VERSION ""

NS_ :

BS_:

BU_: IMU C70 PIT IRTEMP

BO_ 1791 C70_BrakePressures: 8 C70
 SG_ C70_BrakePressureFront : 0|16@1- (0.2,1250) [0|2500] "psi" Vector__XXX
 SG_ C70_BrakePressureRear : 16|16@1- (0.2,1250) [0|2500] "psi" Vector__XXX

BO_ 368 IMU_Sync: 8 Vector__XXX

BO_ 372 IMU_Tx1: 8 IMU
 SG_ IMU_Yaw_Rate : 0|16@1+ (0.005,-163.84) [-163.84|163.83] "deg/s" Vector__XXX
 SG_ IMU_Accel_Y : 32|16@1+ (0.000127465,-4.1768) [-4.1768|4.1765] "g" Vector__XXX

BO_ 376 IMU_Tx2: 8 IMU
 SG_ IMU_Roll_Rate : 0|16@1+ (0.005,-163.84) [-163.84|163.835] "deg/s" Vector__XXX
 SG_ IMU_Accel_X : 32|16@1+ (0.000127465,-4.1768) [-4.1768|4.1765] "g" Vector__XXX

BO_ 380 IMU_Tx3: 8 IMU
 SG_ IMU_Accel_Z : 32|16@1+ (0.000127465,-4.1768) [-4.1768|4.1765] "g" Vector__XXX

BO_ 384 PIT_Pressures: 8 PIT
 SG_ PIT_PressureMux M : 0|8@1+ (1,0) [0|255] "" Vector__XXX
 SG_ PIT_Pressure1 m0 : 15|16@0+ (0.01,600) [600|1200] "mbar" Vector__XXX
 SG_ PIT_Pressure2 m0 : 31|16@0+ (0.01,600) [600|1200] "mbar" Vector__XXX
 SG_ PIT_Pressure3 m0 : 47|16@0+ (0.01,600) [600|1200] "mbar" Vector__XXX
 SG_ PIT_PressureRange m0 : 56|8@1+ (1,0) [0|3] "" Vector__XXX
 SG_ PIT_Pressure4 m1 : 15|16@0+ (0.01,600) [600|1200] "mbar" Vector__XXX
 SG_ PIT_Pressure5 m1 : 31|16@0+ (0.01,600) [600|1200] "mbar" Vector__XXX
 SG_ PIT_Pressure6 m1 : 47|16@0+ (0.01,600) [600|1200] "mbar" Vector__XXX
 SG_ PIT_Temperature m1 : 56|8@1- (1,0) [0|0] "degC" Vector__XXX
 SG_ PIT_Pressure7 m2 : 15|16@0+ (0.01,600) [600|1200] "mbar" Vector__XXX
 SG_ PIT_Pressure8 m2 : 31|16@0+ (0.01,600) [600|1200] "mbar" Vector__XXX
 SG_ PIT_SensorNum m2 : 47|16@0+ (1,0) [0|0] "" Vector__XXX

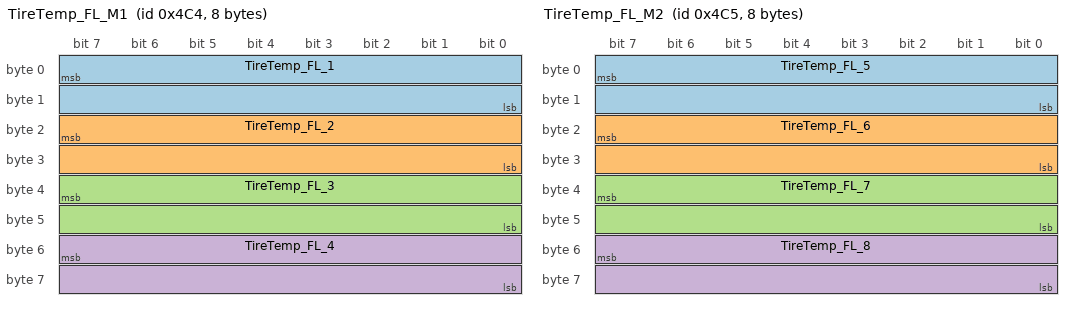
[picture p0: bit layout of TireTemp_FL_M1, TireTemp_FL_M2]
BO_ 1220 TireTemp_FL_M1: 8 IRTEMP
 SG_ TireTemp_FL_1 : 7|16@0+ (0.1,-100) [-20|950] "degC" Vector__XXX
 SG_ TireTemp_FL_2 : 23|16@0+ (0.1,-100) [-20|950] "degC" Vector__XXX
 SG_ TireTemp_FL_3 : 39|16@0+ (0.1,-100) [-20|950] "degC" Vector__XXX
 SG_ TireTemp_FL_4 : 55|16@0+ (0.1,-100) [-20|950] "degC" Vector__XXX

BO_ 1221 TireTemp_FL_M2: 8 IRTEMP
 SG_ TireTemp_FL_5 : 7|16@0+ (0.1,-100) [-20|950] "degC" Vector__XXX
 SG_ TireTemp_FL_6 : 23|16@0+ (0.1,-100) [-20|950] "degC" Vector__XXX
 SG_ TireTemp_FL_7 : 39|16@0+ (0.1,-100) [-20|950] "degC" Vector__XXX
 SG_ TireTemp_FL_8 : 55|16@0+ (0.1,-100) [-20|950] "degC" Vector__XXX

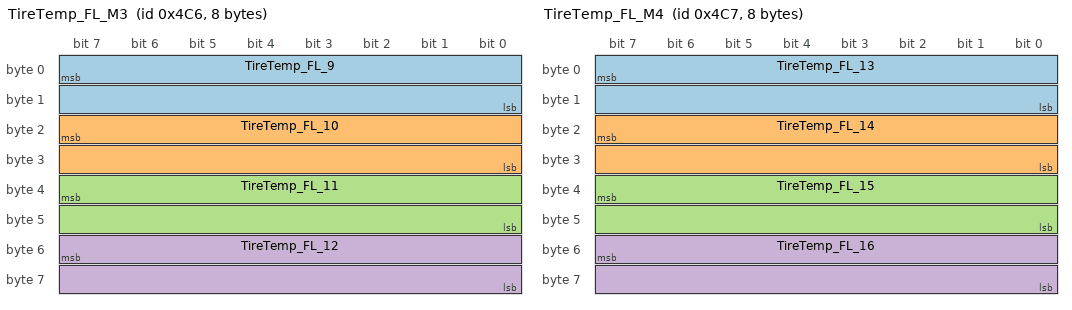
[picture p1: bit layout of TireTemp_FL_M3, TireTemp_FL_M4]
BO_ 1222 TireTemp_FL_M3: 8 IRTEMP
 SG_ TireTemp_FL_9 : 7|16@0+ (0.1,-100) [-20|950] "degC" Vector__XXX
 SG_ TireTemp_FL_10 : 23|16@0+ (0.1,-100) [-20|950] "degC" Vector__XXX
 SG_ TireTemp_FL_11 : 39|16@0+ (0.1,-100) [-20|950] "degC" Vector__XXX
 SG_ TireTemp_FL_12 : 55|16@0+ (0.1,-100) [-20|950] "degC" Vector__XXX

BO_ 1223 TireTemp_FL_M4: 8 IRTEMP
 SG_ TireTemp_FL_13 : 7|16@0+ (0.1,-100) [-20|950] "degC" Vector__XXX
 SG_ TireTemp_FL_14 : 23|16@0+ (0.1,-100) [-20|950] "degC" Vector__XXX
 SG_ TireTemp_FL_15 : 39|16@0+ (0.1,-100) [-20|950] "degC" Vector__XXX
 SG_ TireTemp_FL_16 : 55|16@0+ (0.1,-100) [-20|950] "degC" Vector__XXX

BO_ 1224 TireTemp_FL_M5: 8 IRTEMP
 SG_ TireTemp_FL_Sensor : 7|16@0+ (0.1,-100) [-20|85] "degC" Vector__XXX

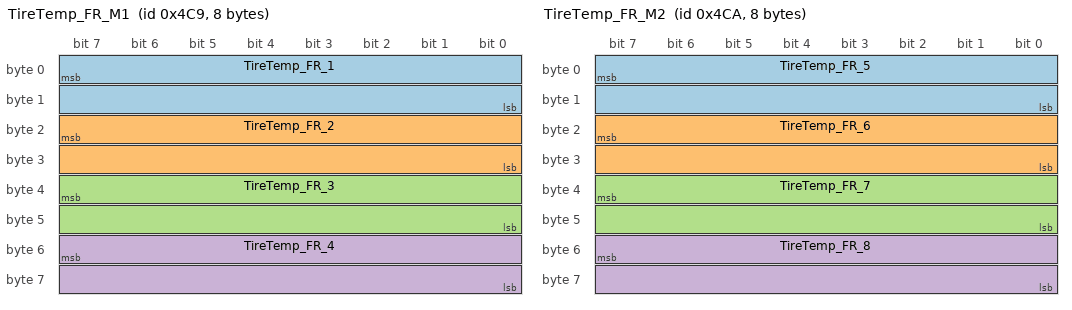
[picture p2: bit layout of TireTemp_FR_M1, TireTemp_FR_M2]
BO_ 1225 TireTemp_FR_M1: 8 IRTEMP
 SG_ TireTemp_FR_1 : 7|16@0+ (0.1,-100) [-20|950] "degC" Vector__XXX
 SG_ TireTemp_FR_2 : 23|16@0+ (0.1,-100) [-20|950] "degC" Vector__XXX
 SG_ TireTemp_FR_3 : 39|16@0+ (0.1,-100) [-20|950] "degC" Vector__XXX
 SG_ TireTemp_FR_4 : 55|16@0+ (0.1,-100) [-20|950] "degC" Vector__XXX

BO_ 1226 TireTemp_FR_M2: 8 IRTEMP
 SG_ TireTemp_FR_5 : 7|16@0+ (0.1,-100) [-20|950] "degC" Vector__XXX
 SG_ TireTemp_FR_6 : 23|16@0+ (0.1,-100) [-20|950] "degC" Vector__XXX
 SG_ TireTemp_FR_7 : 39|16@0+ (0.1,-100) [-20|950] "degC" Vector__XXX
 SG_ TireTemp_FR_8 : 55|16@0+ (0.1,-100) [-20|950] "degC" Vector__XXX

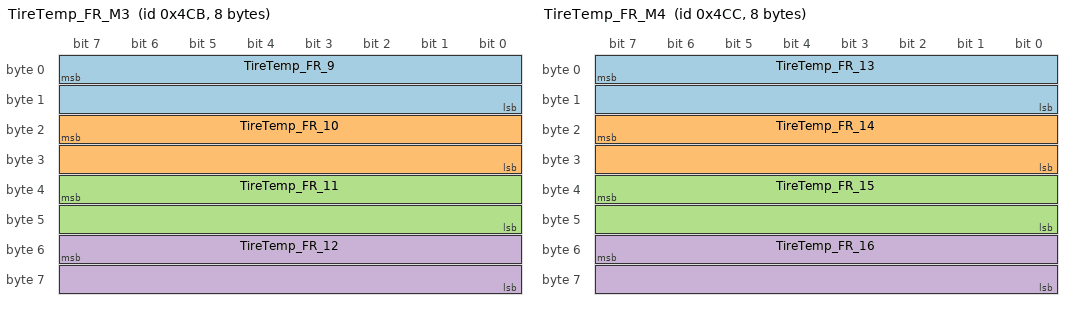
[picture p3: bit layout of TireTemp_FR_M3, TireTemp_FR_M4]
BO_ 1227 TireTemp_FR_M3: 8 IRTEMP
 SG_ TireTemp_FR_9 : 7|16@0+ (0.1,-100) [-20|950] "degC" Vector__XXX
 SG_ TireTemp_FR_10 : 23|16@0+ (0.1,-100) [-20|950] "degC" Vector__XXX
 SG_ TireTemp_FR_11 : 39|16@0+ (0.1,-100) [-20|950] "degC" Vector__XXX
 SG_ TireTemp_FR_12 : 55|16@0+ (0.1,-100) [-20|950] "degC" Vector__XXX

BO_ 1228 TireTemp_FR_M4: 8 IRTEMP
 SG_ TireTemp_FR_13 : 7|16@0+ (0.1,-100) [-20|950] "degC" Vector__XXX
 SG_ TireTemp_FR_14 : 23|16@0+ (0.1,-100) [-20|950] "degC" Vector__XXX
 SG_ TireTemp_FR_15 : 39|16@0+ (0.1,-100) [-20|950] "degC" Vector__XXX
 SG_ TireTemp_FR_16 : 55|16@0+ (0.1,-100) [-20|950] "degC" Vector__XXX

BO_ 1229 TireTemp_FR_M5: 8 IRTEMP
 SG_ TireTemp_FR_Sensor : 7|16@0+ (0.1,-100) [-20|85] "degC" Vector__XXX

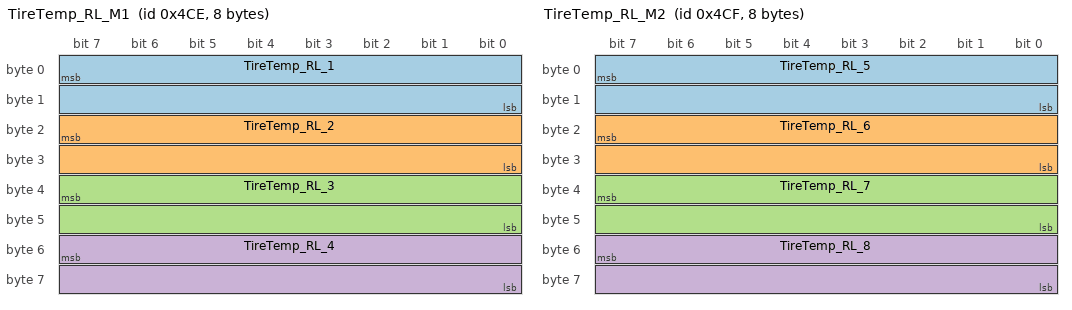
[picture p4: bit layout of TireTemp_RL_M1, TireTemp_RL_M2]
BO_ 1230 TireTemp_RL_M1: 8 IRTEMP
 SG_ TireTemp_RL_1 : 7|16@0+ (0.1,-100) [-20|950] "degC" Vector__XXX
 SG_ TireTemp_RL_2 : 23|16@0+ (0.1,-100) [-20|950] "degC" Vector__XXX
 SG_ TireTemp_RL_3 : 39|16@0+ (0.1,-100) [-20|950] "degC" Vector__XXX
 SG_ TireTemp_RL_4 : 55|16@0+ (0.1,-100) [-20|950] "degC" Vector__XXX

BO_ 1231 TireTemp_RL_M2: 8 IRTEMP
 SG_ TireTemp_RL_5 : 7|16@0+ (0.1,-100) [-20|950] "degC" Vector__XXX
 SG_ TireTemp_RL_6 : 23|16@0+ (0.1,-100) [-20|950] "degC" Vector__XXX
 SG_ TireTemp_RL_7 : 39|16@0+ (0.1,-100) [-20|950] "degC" Vector__XXX
 SG_ TireTemp_RL_8 : 55|16@0+ (0.1,-100) [-20|950] "degC" Vector__XXX

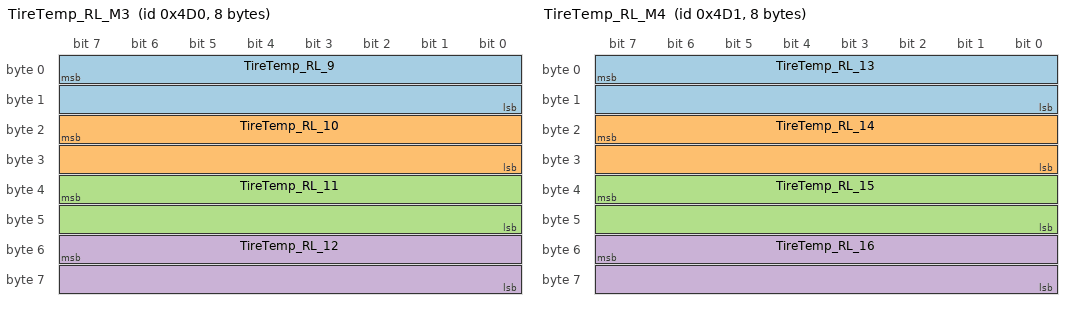
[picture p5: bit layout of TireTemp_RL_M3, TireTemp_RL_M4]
BO_ 1232 TireTemp_RL_M3: 8 IRTEMP
 SG_ TireTemp_RL_9 : 7|16@0+ (0.1,-100) [-20|950] "degC" Vector__XXX
 SG_ TireTemp_RL_10 : 23|16@0+ (0.1,-100) [-20|950] "degC" Vector__XXX
 SG_ TireTemp_RL_11 : 39|16@0+ (0.1,-100) [-20|950] "degC" Vector__XXX
 SG_ TireTemp_RL_12 : 55|16@0+ (0.1,-100) [-20|950] "degC" Vector__XXX

BO_ 1233 TireTemp_RL_M4: 8 IRTEMP
 SG_ TireTemp_RL_13 : 7|16@0+ (0.1,-100) [-20|950] "degC" Vector__XXX
 SG_ TireTemp_RL_14 : 23|16@0+ (0.1,-100) [-20|950] "degC" Vector__XXX
 SG_ TireTemp_RL_15 : 39|16@0+ (0.1,-100) [-20|950] "degC" Vector__XXX
 SG_ TireTemp_RL_16 : 55|16@0+ (0.1,-100) [-20|950] "degC" Vector__XXX

BO_ 1234 TireTemp_RL_M5: 8 IRTEMP
 SG_ TireTemp_RL_Sensor : 7|16@0+ (0.1,-100) [-20|85] "degC" Vector__XXX

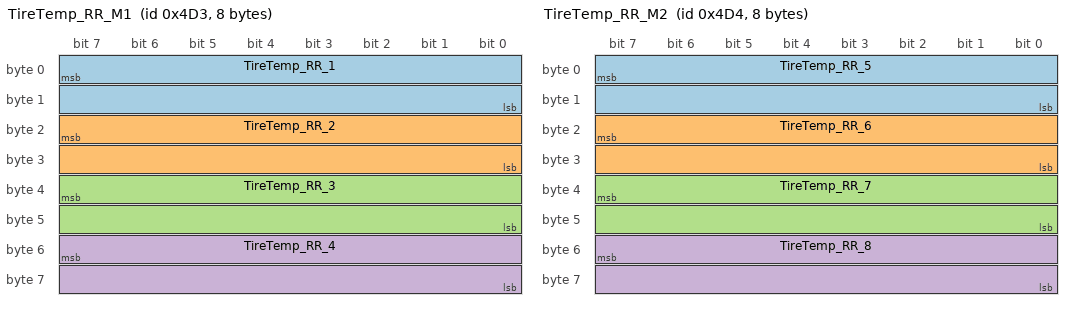
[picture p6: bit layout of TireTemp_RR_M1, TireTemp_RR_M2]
BO_ 1235 TireTemp_RR_M1: 8 IRTEMP
 SG_ TireTemp_RR_1 : 7|16@0+ (0.1,-100) [-20|950] "degC" Vector__XXX
 SG_ TireTemp_RR_2 : 23|16@0+ (0.1,-100) [-20|950] "degC" Vector__XXX
 SG_ TireTemp_RR_3 : 39|16@0+ (0.1,-100) [-20|950] "degC" Vector__XXX
 SG_ TireTemp_RR_4 : 55|16@0+ (0.1,-100) [-20|950] "degC" Vector__XXX

BO_ 1236 TireTemp_RR_M2: 8 IRTEMP
 SG_ TireTemp_RR_5 : 7|16@0+ (0.1,-100) [-20|950] "degC" Vector__XXX
 SG_ TireTemp_RR_6 : 23|16@0+ (0.1,-100) [-20|950] "degC" Vector__XXX
 SG_ TireTemp_RR_7 : 39|16@0+ (0.1,-100) [-20|950] "degC" Vector__XXX
 SG_ TireTemp_RR_8 : 55|16@0+ (0.1,-100) [-20|950] "degC" Vector__XXX

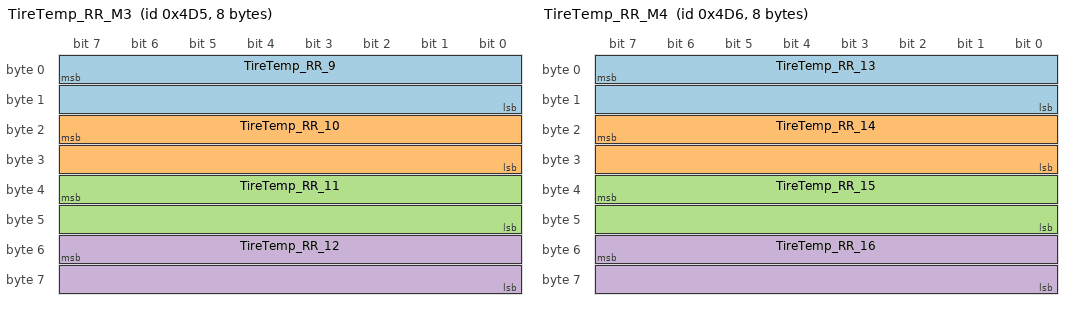
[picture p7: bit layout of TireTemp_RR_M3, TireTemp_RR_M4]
BO_ 1237 TireTemp_RR_M3: 8 IRTEMP
 SG_ TireTemp_RR_9 : 7|16@0+ (0.1,-100) [-20|950] "degC" Vector__XXX
 SG_ TireTemp_RR_10 : 23|16@0+ (0.1,-100) [-20|950] "degC" Vector__XXX
 SG_ TireTemp_RR_11 : 39|16@0+ (0.1,-100) [-20|950] "degC" Vector__XXX
 SG_ TireTemp_RR_12 : 55|16@0+ (0.1,-100) [-20|950] "degC" Vector__XXX

BO_ 1238 TireTemp_RR_M4: 8 IRTEMP
 SG_ TireTemp_RR_13 : 7|16@0+ (0.1,-100) [-20|950] "degC" Vector__XXX
 SG_ TireTemp_RR_14 : 23|16@0+ (0.1,-100) [-20|950] "degC" Vector__XXX
 SG_ TireTemp_RR_15 : 39|16@0+ (0.1,-100) [-20|950] "degC" Vector__XXX
 SG_ TireTemp_RR_16 : 55|16@0+ (0.1,-100) [-20|950] "degC" Vector__XXX

BO_ 1239 TireTemp_RR_M5: 8 IRTEMP
 SG_ TireTemp_RR_Sensor : 7|16@0+ (0.1,-100) [-20|85] "degC" Vector__XXX

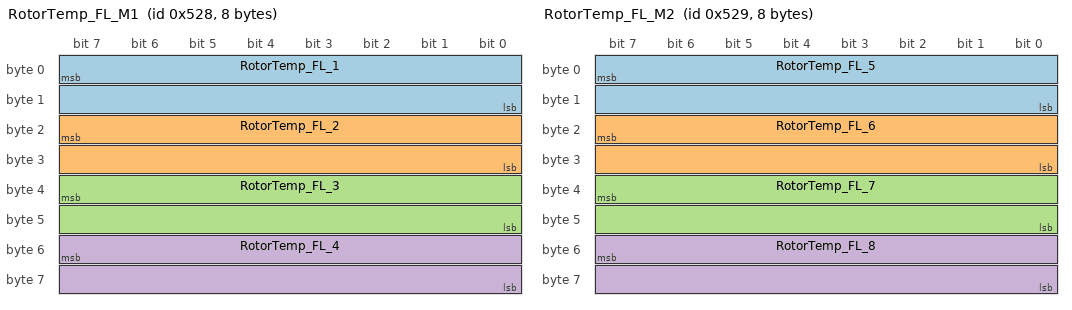
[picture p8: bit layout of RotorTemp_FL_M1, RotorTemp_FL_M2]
BO_ 1320 RotorTemp_FL_M1: 8 IRTEMP
 SG_ RotorTemp_FL_1 : 7|16@0+ (0.1,-100) [-20|950] "degC" Vector__XXX
 SG_ RotorTemp_FL_2 : 23|16@0+ (0.1,-100) [-20|950] "degC" Vector__XXX
 SG_ RotorTemp_FL_3 : 39|16@0+ (0.1,-100) [-20|950] "degC" Vector__XXX
 SG_ RotorTemp_FL_4 : 55|16@0+ (0.1,-100) [-20|950] "degC" Vector__XXX

BO_ 1321 RotorTemp_FL_M2: 8 IRTEMP
 SG_ RotorTemp_FL_5 : 7|16@0+ (0.1,-100) [-20|950] "degC" Vector__XXX
 SG_ RotorTemp_FL_6 : 23|16@0+ (0.1,-100) [-20|950] "degC" Vector__XXX
 SG_ RotorTemp_FL_7 : 39|16@0+ (0.1,-100) [-20|950] "degC" Vector__XXX
 SG_ RotorTemp_FL_8 : 55|16@0+ (0.1,-100) [-20|950] "degC" Vector__XXX

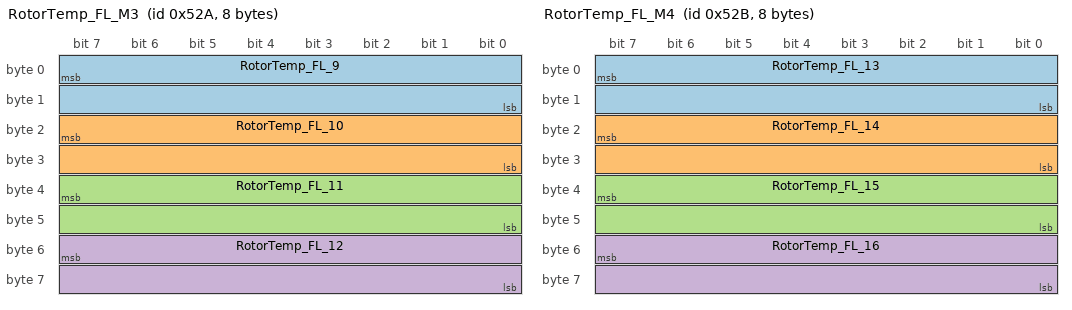
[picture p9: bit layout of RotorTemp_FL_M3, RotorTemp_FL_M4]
BO_ 1322 RotorTemp_FL_M3: 8 IRTEMP
 SG_ RotorTemp_FL_9 : 7|16@0+ (0.1,-100) [-20|950] "degC" Vector__XXX
 SG_ RotorTemp_FL_10 : 23|16@0+ (0.1,-100) [-20|950] "degC" Vector__XXX
 SG_ RotorTemp_FL_11 : 39|16@0+ (0.1,-100) [-20|950] "degC" Vector__XXX
 SG_ RotorTemp_FL_12 : 55|16@0+ (0.1,-100) [-20|950] "degC" Vector__XXX

BO_ 1323 RotorTemp_FL_M4: 8 IRTEMP
 SG_ RotorTemp_FL_13 : 7|16@0+ (0.1,-100) [-20|950] "degC" Vector__XXX
 SG_ RotorTemp_FL_14 : 23|16@0+ (0.1,-100) [-20|950] "degC" Vector__XXX
 SG_ RotorTemp_FL_15 : 39|16@0+ (0.1,-100) [-20|950] "degC" Vector__XXX
 SG_ RotorTemp_FL_16 : 55|16@0+ (0.1,-100) [-20|950] "degC" Vector__XXX

BO_ 1324 RotorTemp_FL_M5: 8 IRTEMP
 SG_ RotorTemp_FL_Sensor : 7|16@0+ (0.1,-100) [-20|85] "degC" Vector__XXX

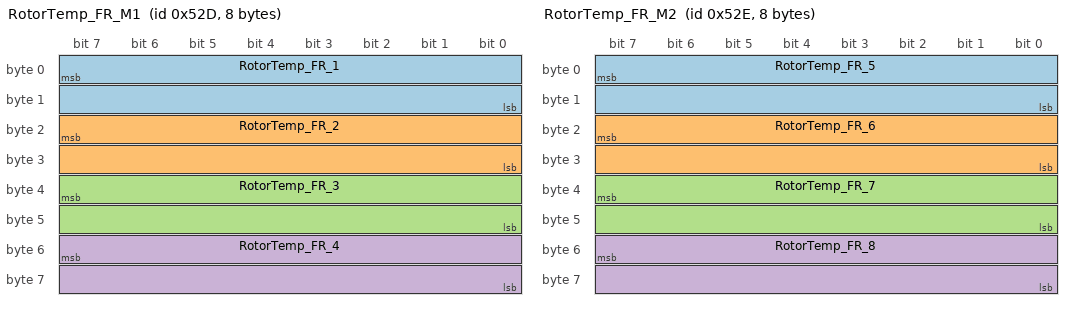
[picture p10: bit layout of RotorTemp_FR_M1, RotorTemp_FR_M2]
BO_ 1325 RotorTemp_FR_M1: 8 IRTEMP
 SG_ RotorTemp_FR_1 : 7|16@0+ (0.1,-100) [-20|950] "degC" Vector__XXX
 SG_ RotorTemp_FR_2 : 23|16@0+ (0.1,-100) [-20|950] "degC" Vector__XXX
 SG_ RotorTemp_FR_3 : 39|16@0+ (0.1,-100) [-20|950] "degC" Vector__XXX
 SG_ RotorTemp_FR_4 : 55|16@0+ (0.1,-100) [-20|950] "degC" Vector__XXX

BO_ 1326 RotorTemp_FR_M2: 8 IRTEMP
 SG_ RotorTemp_FR_5 : 7|16@0+ (0.1,-100) [-20|950] "degC" Vector__XXX
 SG_ RotorTemp_FR_6 : 23|16@0+ (0.1,-100) [-20|950] "degC" Vector__XXX
 SG_ RotorTemp_FR_7 : 39|16@0+ (0.1,-100) [-20|950] "degC" Vector__XXX
 SG_ RotorTemp_FR_8 : 55|16@0+ (0.1,-100) [-20|950] "degC" Vector__XXX

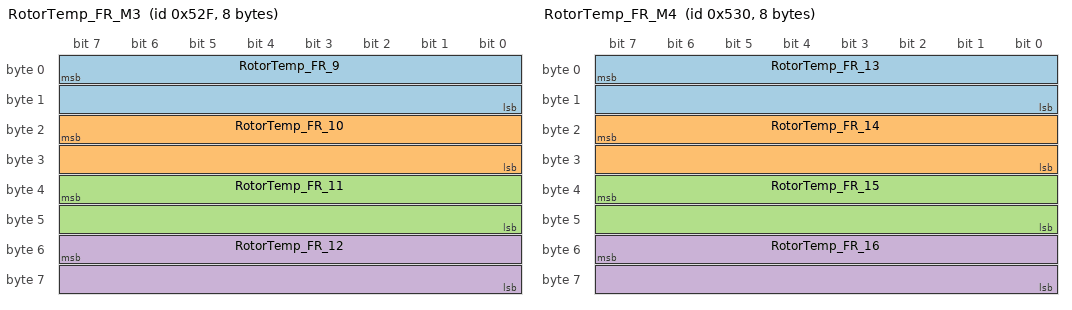
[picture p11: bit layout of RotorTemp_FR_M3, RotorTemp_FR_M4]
BO_ 1327 RotorTemp_FR_M3: 8 IRTEMP
 SG_ RotorTemp_FR_9 : 7|16@0+ (0.1,-100) [-20|950] "degC" Vector__XXX
 SG_ RotorTemp_FR_10 : 23|16@0+ (0.1,-100) [-20|950] "degC" Vector__XXX
 SG_ RotorTemp_FR_11 : 39|16@0+ (0.1,-100) [-20|950] "degC" Vector__XXX
 SG_ RotorTemp_FR_12 : 55|16@0+ (0.1,-100) [-20|950] "degC" Vector__XXX

BO_ 1328 RotorTemp_FR_M4: 8 IRTEMP
 SG_ RotorTemp_FR_13 : 7|16@0+ (0.1,-100) [-20|950] "degC" Vector__XXX
 SG_ RotorTemp_FR_14 : 23|16@0+ (0.1,-100) [-20|950] "degC" Vector__XXX
 SG_ RotorTemp_FR_15 : 39|16@0+ (0.1,-100) [-20|950] "degC" Vector__XXX
 SG_ RotorTemp_FR_16 : 55|16@0+ (0.1,-100) [-20|950] "degC" Vector__XXX

BO_ 1329 RotorTemp_FR_M5: 8 IRTEMP
 SG_ RotorTemp_FR_Sensor : 7|16@0+ (0.1,-100) [-20|85] "degC" Vector__XXX

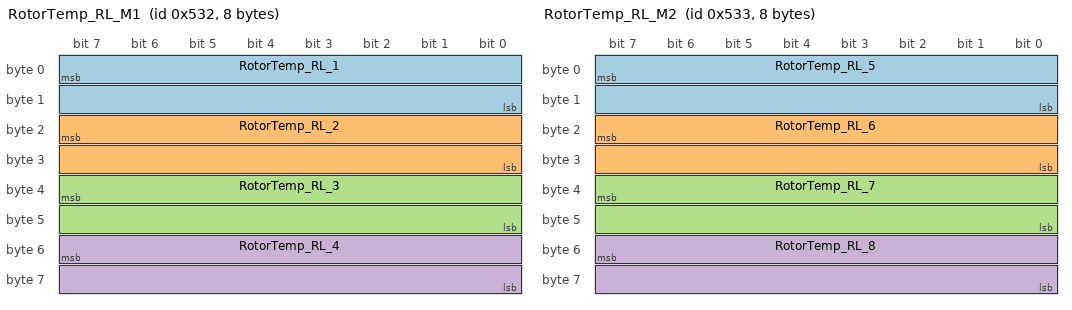
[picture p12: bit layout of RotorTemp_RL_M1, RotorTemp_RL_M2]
BO_ 1330 RotorTemp_RL_M1: 8 IRTEMP
 SG_ RotorTemp_RL_1 : 7|16@0+ (0.1,-100) [-20|950] "degC" Vector__XXX
 SG_ RotorTemp_RL_2 : 23|16@0+ (0.1,-100) [-20|950] "degC" Vector__XXX
 SG_ RotorTemp_RL_3 : 39|16@0+ (0.1,-100) [-20|950] "degC" Vector__XXX
 SG_ RotorTemp_RL_4 : 55|16@0+ (0.1,-100) [-20|950] "degC" Vector__XXX

BO_ 1331 RotorTemp_RL_M2: 8 IRTEMP
 SG_ RotorTemp_RL_5 : 7|16@0+ (0.1,-100) [-20|950] "degC" Vector__XXX
 SG_ RotorTemp_RL_6 : 23|16@0+ (0.1,-100) [-20|950] "degC" Vector__XXX
 SG_ RotorTemp_RL_7 : 39|16@0+ (0.1,-100) [-20|950] "degC" Vector__XXX
 SG_ RotorTemp_RL_8 : 55|16@0+ (0.1,-100) [-20|950] "degC" Vector__XXX

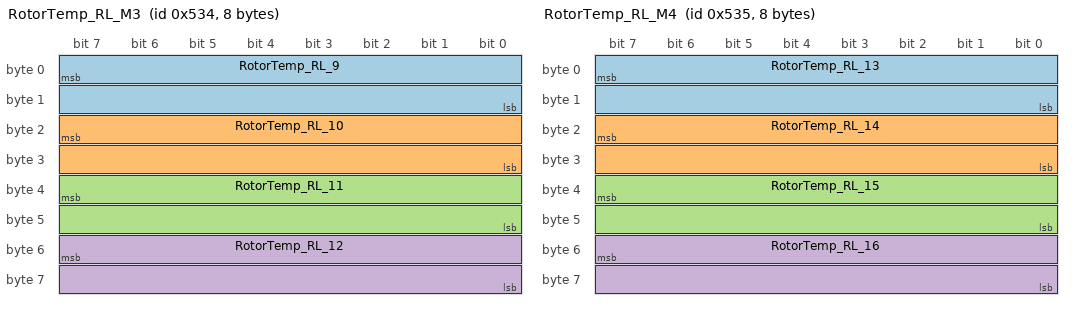
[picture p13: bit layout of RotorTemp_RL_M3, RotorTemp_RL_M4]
BO_ 1332 RotorTemp_RL_M3: 8 IRTEMP
 SG_ RotorTemp_RL_9 : 7|16@0+ (0.1,-100) [-20|950] "degC" Vector__XXX
 SG_ RotorTemp_RL_10 : 23|16@0+ (0.1,-100) [-20|950] "degC" Vector__XXX
 SG_ RotorTemp_RL_11 : 39|16@0+ (0.1,-100) [-20|950] "degC" Vector__XXX
 SG_ RotorTemp_RL_12 : 55|16@0+ (0.1,-100) [-20|950] "degC" Vector__XXX

BO_ 1333 RotorTemp_RL_M4: 8 IRTEMP
 SG_ RotorTemp_RL_13 : 7|16@0+ (0.1,-100) [-20|950] "degC" Vector__XXX
 SG_ RotorTemp_RL_14 : 23|16@0+ (0.1,-100) [-20|950] "degC" Vector__XXX
 SG_ RotorTemp_RL_15 : 39|16@0+ (0.1,-100) [-20|950] "degC" Vector__XXX
 SG_ RotorTemp_RL_16 : 55|16@0+ (0.1,-100) [-20|950] "degC" Vector__XXX

BO_ 1334 RotorTemp_RL_M5: 8 IRTEMP
 SG_ RotorTemp_RL_Sensor : 7|16@0+ (0.1,-100) [-20|85] "degC" Vector__XXX

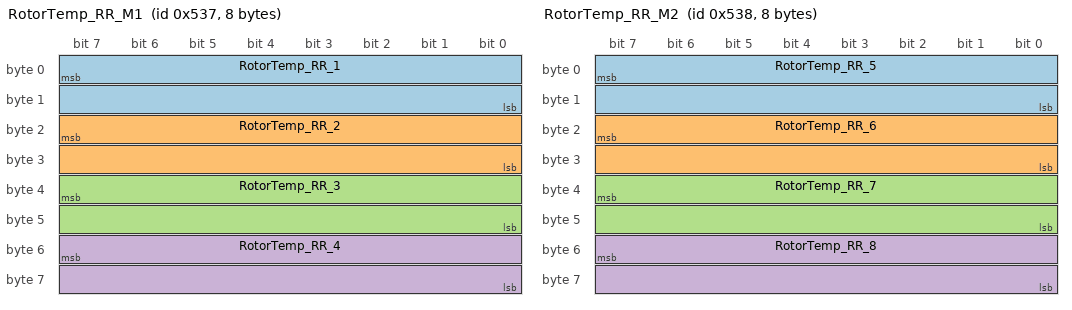
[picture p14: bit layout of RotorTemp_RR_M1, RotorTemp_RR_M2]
BO_ 1335 RotorTemp_RR_M1: 8 IRTEMP
 SG_ RotorTemp_RR_1 : 7|16@0+ (0.1,-100) [-20|950] "degC" Vector__XXX
 SG_ RotorTemp_RR_2 : 23|16@0+ (0.1,-100) [-20|950] "degC" Vector__XXX
 SG_ RotorTemp_RR_3 : 39|16@0+ (0.1,-100) [-20|950] "degC" Vector__XXX
 SG_ RotorTemp_RR_4 : 55|16@0+ (0.1,-100) [-20|950] "degC" Vector__XXX

BO_ 1336 RotorTemp_RR_M2: 8 IRTEMP
 SG_ RotorTemp_RR_5 : 7|16@0+ (0.1,-100) [-20|950] "degC" Vector__XXX
 SG_ RotorTemp_RR_6 : 23|16@0+ (0.1,-100) [-20|950] "degC" Vector__XXX
 SG_ RotorTemp_RR_7 : 39|16@0+ (0.1,-100) [-20|950] "degC" Vector__XXX
 SG_ RotorTemp_RR_8 : 55|16@0+ (0.1,-100) [-20|950] "degC" Vector__XXX

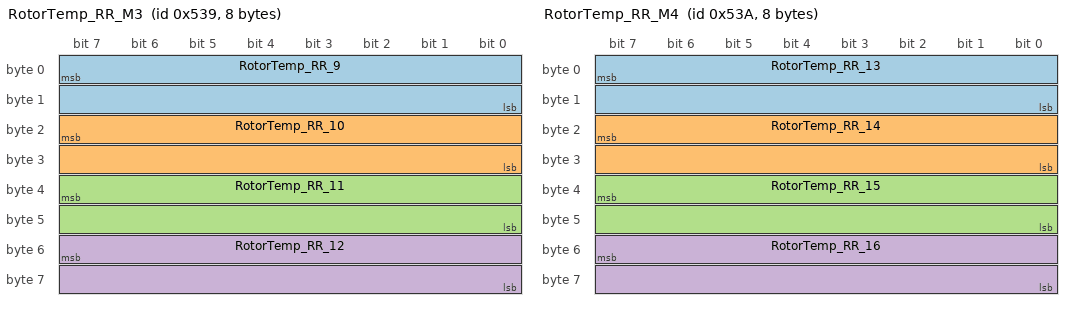
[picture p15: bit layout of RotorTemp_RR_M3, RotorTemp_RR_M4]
BO_ 1337 RotorTemp_RR_M3: 8 IRTEMP
 SG_ RotorTemp_RR_9 : 7|16@0+ (0.1,-100) [-20|950] "degC" Vector__XXX
 SG_ RotorTemp_RR_10 : 23|16@0+ (0.1,-100) [-20|950] "degC" Vector__XXX
 SG_ RotorTemp_RR_11 : 39|16@0+ (0.1,-100) [-20|950] "degC" Vector__XXX
 SG_ RotorTemp_RR_12 : 55|16@0+ (0.1,-100) [-20|950] "degC" Vector__XXX

BO_ 1338 RotorTemp_RR_M4: 8 IRTEMP
 SG_ RotorTemp_RR_13 : 7|16@0+ (0.1,-100) [-20|950] "degC" Vector__XXX
 SG_ RotorTemp_RR_14 : 23|16@0+ (0.1,-100) [-20|950] "degC" Vector__XXX
 SG_ RotorTemp_RR_15 : 39|16@0+ (0.1,-100) [-20|950] "degC" Vector__XXX
 SG_ RotorTemp_RR_16 : 55|16@0+ (0.1,-100) [-20|950] "degC" Vector__XXX

BO_ 1339 RotorTemp_RR_M5: 8 IRTEMP
 SG_ RotorTemp_RR_Sensor : 7|16@0+ (0.1,-100) [-20|85] "degC" Vector__XXX

CM_ BU_ IMU "Bosch MM5.10 Inertial Measurement Unit";
CM_ BU_ C70 "Bosch C70 Data Logger";
CM_ BU_ PIT "EvoScann P8-A Pressure Sensor";
CM_ BU_ IRTEMP "Izze IRTS-60 v2 IR Temperature Sensors";
